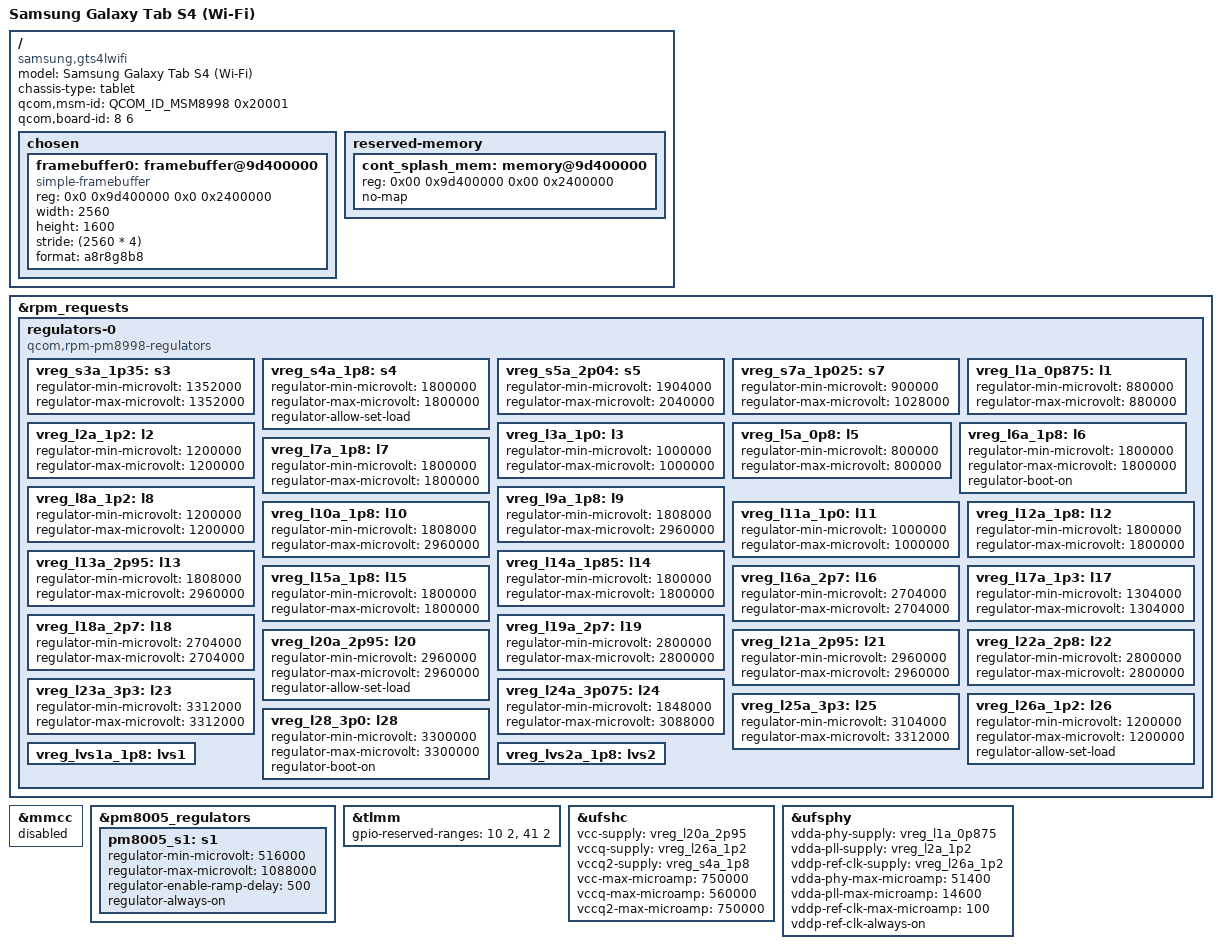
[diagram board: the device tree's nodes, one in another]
// SPDX-License-Identifier: GPL-2.0
/*
 * Copyright (c) 2024, David Wronek <david@mainlining.org>
 */

/dts-v1/;

#include <dt-bindings/arm/qcom,ids.h>
#include <dt-bindings/pinctrl/qcom,pmic-gpio.h>
#include "msm8998.dtsi"
#include "pm8005.dtsi"
#include "pm8998.dtsi"

/ {
	model = "Samsung Galaxy Tab S4 (Wi-Fi)";
	compatible = "samsung,gts4lwifi", "qcom,msm8998";
	chassis-type = "tablet";

	qcom,msm-id = <QCOM_ID_MSM8998 0x20001>;
	qcom,board-id = <8 6>;

	chosen {
		#address-cells = <2>;
		#size-cells = <2>;
		ranges;

		framebuffer0: framebuffer@9d400000 {
			compatible = "simple-framebuffer";
			reg = <0x0 0x9d400000 0x0 0x2400000>;
			width = <2560>;
			height = <1600>;
			stride = <(2560 * 4)>;
			format = "a8r8g8b8";
		};
	};

	reserved-memory {
		cont_splash_mem: memory@9d400000 {
			reg = <0x00 0x9d400000 0x00 0x2400000>;
			no-map;
		};
	};
};

&rpm_requests {
	regulators-0 {
		compatible = "qcom,rpm-pm8998-regulators";

		vreg_s3a_1p35: s3 {
			regulator-min-microvolt = <1352000>;
			regulator-max-microvolt = <1352000>;
		};

		vreg_s4a_1p8: s4 {
			regulator-min-microvolt = <1800000>;
			regulator-max-microvolt = <1800000>;
			regulator-allow-set-load;
		};

		vreg_s5a_2p04: s5 {
			regulator-min-microvolt = <1904000>;
			regulator-max-microvolt = <2040000>;
		};

		vreg_s7a_1p025: s7 {
			regulator-min-microvolt = <900000>;
			regulator-max-microvolt = <1028000>;
		};

		vreg_l1a_0p875: l1 {
			regulator-min-microvolt = <880000>;
			regulator-max-microvolt = <880000>;
		};

		vreg_l2a_1p2: l2 {
			regulator-min-microvolt = <1200000>;
			regulator-max-microvolt = <1200000>;
		};

		vreg_l3a_1p0: l3 {
			regulator-min-microvolt = <1000000>;
			regulator-max-microvolt = <1000000>;
		};

		vreg_l5a_0p8: l5 {
			regulator-min-microvolt = <800000>;
			regulator-max-microvolt = <800000>;
		};

		vreg_l6a_1p8: l6 {
			regulator-min-microvolt = <1800000>;
			regulator-max-microvolt = <1800000>;
			regulator-boot-on;
		};

		vreg_l7a_1p8: l7 {
			regulator-min-microvolt = <1800000>;
			regulator-max-microvolt = <1800000>;
		};

		vreg_l8a_1p2: l8 {
			regulator-min-microvolt = <1200000>;
			regulator-max-microvolt = <1200000>;
		};

		vreg_l9a_1p8: l9 {
			regulator-min-microvolt = <1808000>;
			regulator-max-microvolt = <2960000>;
		};

		vreg_l10a_1p8: l10 {
			regulator-min-microvolt = <1808000>;
			regulator-max-microvolt = <2960000>;
		};

		vreg_l11a_1p0: l11 {
			regulator-min-microvolt = <1000000>;
			regulator-max-microvolt = <1000000>;
		};

		vreg_l12a_1p8: l12 {
			regulator-min-microvolt = <1800000>;
			regulator-max-microvolt = <1800000>;
		};

		vreg_l13a_2p95: l13 {
			regulator-min-microvolt = <1808000>;
			regulator-max-microvolt = <2960000>;
		};

		vreg_l14a_1p85: l14 {
			regulator-min-microvolt = <1800000>;
			regulator-max-microvolt = <1800000>;
		};

		vreg_l15a_1p8: l15 {
			regulator-min-microvolt = <1800000>;
			regulator-max-microvolt = <1800000>;
		};

		vreg_l16a_2p7: l16 {
			regulator-min-microvolt = <2704000>;
			regulator-max-microvolt = <2704000>;
		};

		vreg_l17a_1p3: l17 {
			regulator-min-microvolt = <1304000>;
			regulator-max-microvolt = <1304000>;
		};

		vreg_l18a_2p7: l18 {
			regulator-min-microvolt = <2704000>;
			regulator-max-microvolt = <2704000>;
		};

		vreg_l19a_2p7: l19 {
			regulator-min-microvolt = <2800000>;
			regulator-max-microvolt = <2800000>;
		};

		vreg_l20a_2p95: l20 {
			regulator-min-microvolt = <2960000>;
			regulator-max-microvolt = <2960000>;
			regulator-allow-set-load;
		};

		vreg_l21a_2p95: l21 {
			regulator-min-microvolt = <2960000>;
			regulator-max-microvolt = <2960000>;
		};

		vreg_l22a_2p8: l22 {
			regulator-min-microvolt = <2800000>;
			regulator-max-microvolt = <2800000>;
		};

		vreg_l23a_3p3: l23 {
			regulator-min-microvolt = <3312000>;
			regulator-max-microvolt = <3312000>;
		};

		vreg_l24a_3p075: l24 {
			regulator-min-microvolt = <1848000>;
			regulator-max-microvolt = <3088000>;
		};

		vreg_l25a_3p3: l25 {
			regulator-min-microvolt = <3104000>;
			regulator-max-microvolt = <3312000>;
		};

		vreg_l26a_1p2: l26 {
			regulator-min-microvolt = <1200000>;
			regulator-max-microvolt = <1200000>;
			regulator-allow-set-load;
		};

		vreg_l28_3p0: l28 {
			regulator-min-microvolt = <3300000>;
			regulator-max-microvolt = <3300000>;
			regulator-boot-on;
		};

		vreg_lvs1a_1p8: lvs1 { };

		vreg_lvs2a_1p8: lvs2 { };
	};
};

&mmcc {
    /* Disable MMCC until we have a proper panel driver */
    status = "disabled";
};

&pm8005_regulators {
	/* VDD_GFX supply */
	pm8005_s1: s1 {
		regulator-min-microvolt = <516000>;
		regulator-max-microvolt = <1088000>;
		regulator-enable-ramp-delay = <500>;
		/* Hack until we rig up the gpu consumer */
		regulator-always-on;
	};
};

&tlmm {
	gpio-reserved-ranges = <10 2>, <41 2>;
};

&ufshc {
	vcc-supply = <&vreg_l20a_2p95>;
	vccq-supply = <&vreg_l26a_1p2>;
	vccq2-supply = <&vreg_s4a_1p8>;
	vcc-max-microamp = <750000>;
	vccq-max-microamp = <560000>;
	vccq2-max-microamp = <750000>;

	status = "okay";
};

&ufsphy {
	vdda-phy-supply = <&vreg_l1a_0p875>;
	vdda-pll-supply = <&vreg_l2a_1p2>;
	vddp-ref-clk-supply = <&vreg_l26a_1p2>;
	vdda-phy-max-microamp = <51400>;
	vdda-pll-max-microamp = <14600>;
	vddp-ref-clk-max-microamp = <100>;
	vddp-ref-clk-always-on;

	status = "okay";
};
